# DISPC_VP1 register map
Vendor: Texas Instruments
Peripheral module from a debugger description file (folder TDA3x).
Registers are 32-bit, access per field, reset 0x0 unless marked. A register's access mark holds for its fields unless they carry their own. Offsets are as the file gives them; lines under a group give offsets from that group; [hi:lo] are bit positions; {n}, {i} and the like mark numbered series; 'fields as' and 'values as' point back to an identical list; <NAME> marks a mode.

## DISPC_VP1
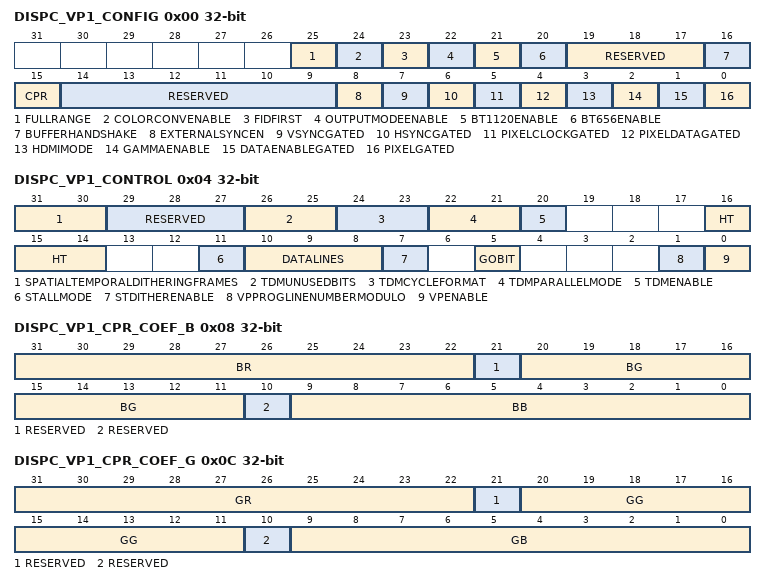
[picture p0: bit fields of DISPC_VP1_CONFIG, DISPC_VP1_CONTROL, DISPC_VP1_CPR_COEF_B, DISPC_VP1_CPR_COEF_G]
0x00 DISPC_VP1_CONFIG — The control register configures the Display Controller module for the VP output. Shadow register. Note: DSI, RFBI and HDMI are not supported in this family of devices.
  [25] FULLRANGE rw — Color Space Conversion full range setting.
    0=LIMRANGE (Limited range selected.); 1=FULLRANGE (Full range selected.)
  [24] COLORCONVENABLE rw — Enable the color space conversion. It shall be reset when CPR bit-field is set to 0x1.
    0=COLSPCDIS (Disable Color Space Conversion RGB to YUV); 1=COLSPCENB (Enable Color Space Conversion RGB to YUV)
  [23] FIDFIRST rw — Selects the first field to output in case of interlace mode. In case of progressive mode, the value is not used.
    0=EVEN (First field is even.); 1=ODD (Odd field is first.)
  [22] OUTPUTMODEENABLE rw — Selects between progressive and interlace mode for the VP output.
    0=DISABLE (Progressive mode selected.); 1=ENABLE (Interlace mode selected.)
  [21] BT1120ENABLE rw — Selects BT-1120 format on the VP output. It is not posssible to enable BT656 and BT1120 at the same time on the same VP output.
    0=DISABLE (BT-1120 is disabled.); 1=ENABLE (BT-1120 is enabled.)
  [20] BT656ENABLE rw — Selects BT-656 format on the VP output. It is not posssible to enable BT656 and BT1120 at the same time on the same VP output.
    0=DISABLE (BT-656 is disabled.); 1=ENABLE (BT-656 is enabled.)
  [19:17] RESERVED ro — Write 0's for future compatibility. Reads return 0
  [16] BUFFERHANDSHAKE rw — Controls the handsSHAKE between DMA buffer and STALL signal in order to prevent from underflow. The bit shall be set to 0 when the module is not in STALL mode.
    0=HANDCHECKDIS (Only the STALL signal (generated by RFBI or DSI2 depending on which IP uses the LCD output) is used regardless of the DMA buffer fullness information in order to provide data to the RFBI or DSI2 module.); 1=HANDCHECKENB (The STALL signal (generated by RFBI or DSI2 depending on which IP uses the LCD output) is used in combination with the DMA buffer fullness information in order to provide data to the RFBI or DSI2 module only when it does not generated buffer underflow.)
  [15] CPR rw — Color Phase Rotation Control VP output). It shall be reset when ColorConvEnable bit-field is set to 1. Shadow bit-field.
    0=CPRDIS (Color Phase Rotation Disabled); 1=CPRENB (Color Phase Rotation Enabled)
  [14:9] RESERVED ro — Write 0's for future compatibility. Reads return 0
  [8] EXTERNALSYNCEN rw — Selects between external sync and internal sync mode for the VP output.
    0=DISABLE (Internal sync mode selected); 1=ENABLE (External sync mode selected.)
  [7] VSYNCGATED rw — VSYNC Gated Enabled (VP output) Shadow bit-field.
    0=VGDIS (VSYNC Gated Disabled); 1=VGENB (VSYNC Gated Enabled)
  [6] HSYNCGATED rw — HSYNC Gated Enabled (VP output) Shadow bit-field.
    0=HGDIS (HSYNC Gated Disabled); 1=HGENB (HSYNC Gated Enabled)
  [5] PIXELCLOCKGATED rw — Pixel Clock Gated Enabled (VP output) Shadow bit-field.
    0=PCGDIS (Pixel Clock Gated Disabled); 1=PCGENB (Pixel Clock Gated Enabled)
  [4] PIXELDATAGATED rw — Pixel Data Gated Enabled (VP output) Shadow bit-field.
    0=PDGDIS (Pixel Data Gated Disabled); 1=PDGENB (Pixel Data Gated Enabled)
  [3] HDMIMODE rw — Configures the timing generator in HDMI compatible mode to generate same timings as HDMI wrapper timings.
    0=HDMIMODEDIS (Disable HDMI mode.); 1=HDMIMODEEN (Enable HDMI mode timings: - vertical FSM starts with the VFP period (instead of VSYNC) - last frame ends with the last pixel of data state.)
  [2] GAMMAENABLE rw — Enable the gamma Shadow bit-field.
    0=GAMMADIS (Gamma disabled); 1=GAMMAENB (Gamma enabled)
  [1] DATAENABLEGATED rw — DE Gated Enable Shadow bit-field.
    0=DEGDIS (DE signal is not gated); 1=DEGENB (DE signal is gated.)
  [0] PIXELGATED rw — Pixel Gated Enable Shadow bit-field.
    0=PCLKTOGA (Pixel clock always toggles (only in TFT mode)); 1=PCLKTOGV (Pixel clock only toggles when there is valid data to display. (only in TFT mode))
0x04 DISPC_VP1_CONTROL — The control register configures the Display Controller module for the VP output.
  [31:30] SPATIALTEMPORALDITHERINGFRAMES rw — Spatial/Temporal dithering number of frames for the VP output. Shadow bit-field.
    0=ONEFRAME (Spatial only); 1=TWOFRAMES (Spatial and temporal over 2 frames); 2=FOURFRAMES (Spatial and temporal over 4 frames)
  [29:27] RESERVED ro — Write 0's for future compatibility. Reads return 0
  [26:25] TDMUNUSEDBITS rw — State of unused bits (TDM mode only) for the VP output. Shadow bit-field.
    0=LOWLEVEL (low level (0)); 1=HIGHLEVEL (high level (1)); 2=UNCHANGED (unchanged from previous state)
  [24:23] TDMCYCLEFORMAT rw — Cycle format (TDM mode only) for the VP output. Shadow bit-field.
    0=_1CYCPERPIX (1 cycle for 1 pixel); 1=_2CYCPERPIX (2 cycles for 1 pixel); 3=_3CYCPER2PIX (3 cycles for 2 pixels); 2=_3CYCPERPIX (3 cycles for 1 pixel)
  [22:21] TDMPARALLELMODE rw — Output Interface width (TDM mode only) for the VP output. Shadow bit-field.
    0=_8BPARAINT (8-bit parallel output interface selected); 1=_9BPARAINT (9-bit parallel output interface selected); 3=_16BPARAINT (16-bit parallel output interface selected); 2=_12BPARAINT (12-bit parallel output interface selected)
  [20] TDMENABLE rw — Enable the multiple cycle format for the VP output. Shadow bit-field.
    0=TDMDIS (TDM disabled); 1=TDMENB (TDM enabled)
  [16:14] HT rw — Hold Time for VP output. Shadow bit-field. Encoded value (from 1 to 8) to specify the number of external digital clock periods to hold the data (programmed value = value minus one)
  [11] STALLMODE rw — STALL Mode for the VP output. Shadow bit-field.
    0=NMODE (Normal mode selected); 1=RFBIMODE (STALL mode selected. The Display Controller sends the data without considering the VSYNC/HSYNC. The VP output is disabled at the end of the transfer of the frame. The S/W has to re-enable the VP output in order to generate a new frame.)
  [10:8] DATALINES rw — Width of the data bus on VP output. Shadow bit-field.
    1=OALSB16B (16-bit output aligned on the LSB of the pixel data interface); 0=OALSB12B (12-bit output aligned on the LSB of the pixel data interface); 2=OALSB18B (18-bit output aligned on the LSB of the pixel data interface); 4=OALSB30B (30-bit output aligned on the LSB of the pixel data interface); 5=OALSB36B (36-bit output aligned on the LSB of the pixel data interface); 3=OALSB24B (24-bit output aligned on the LSB of the pixel data interface)
  [7] STDITHERENABLE rw — Spatial Temporal dithering enable for the VP output Shadow bit-field.
    0=STDITHDIS (Spatial/Temporal dithering logic disabled); 1=STDITHENB (Spatial/Temporal dithering logic enabled)
  [5] GOBIT rw — GO Command for the VP output. It is used to synchronized the pipelines associated with the VP output. wr:immediate
    0=HFUISR (The hardware has finished updating the internal shadow registers of the pipeline(s) connected to the VP output using the user values. The hardware resets the bit when the update is completed.); 1=UFPSR (The user has finished to program the shadow registers of the pipeline(s) associated with the VP output and the hardware can update the internal registers at the VFP start period)
  [1] VPPROGLINENUMBERMODULO rw — Enable the modulo of the line number interrupt generation
    0=MODDIS (Disable modulo); 1=MODEN (Enable Modulo)
  [0] VPENABLE rw — Enable the video port output wr:immediate
    0=LCDOPDIS (VP output disabled (at the end of the frame when the bit is reset)); 1=LCDOPENB (VP output enabled)
0x08 DISPC_VP1_CPR_COEF_B — The register configures the color phase rotation matrix coefficients for the Blue component. Shadow register.
  [31:22] BR rw — BR Coefficient Encoded signed value (from -512 to 511).
  [21] RESERVED ro — Write 0's for future compatibility. Reads return 0
  [20:11] BG rw — BG Coefficient Encoded signed value (from -512 to 511).
  [10] RESERVED ro — Write 0's for future compatibility. Reads return 0
  [9:0] BB rw — BB Coefficient Encoded signed value (from -512 to 511).
0x0C DISPC_VP1_CPR_COEF_G — The register configures the color phase rotation matrix coefficients for the Green component. Shadow register.
  [31:22] GR rw — GR Coefficient Encoded signed value (from -512 to 511).
  [21] RESERVED ro — Write 0's for future compatibility. Reads return 0
  [20:11] GG rw — GG Coefficient Encoded signed value (from -512 to 511).
  [10] RESERVED ro — Write 0's for future compatibility. Reads return 0
  [9:0] GB rw — GB Coefficient Encoded signed value (from -512 to 511).
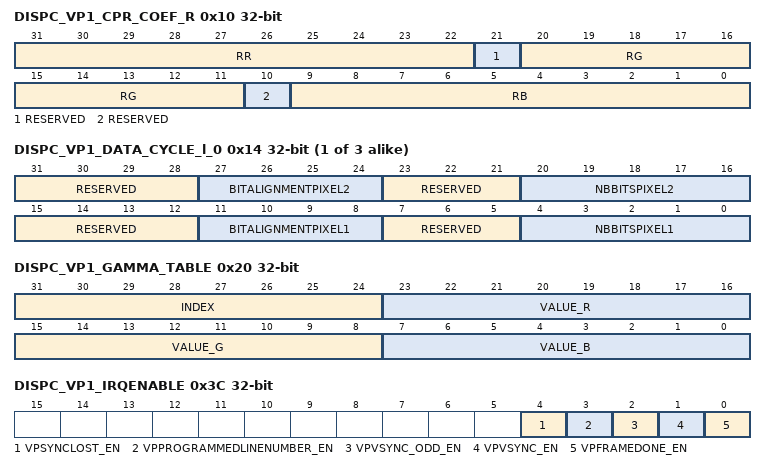
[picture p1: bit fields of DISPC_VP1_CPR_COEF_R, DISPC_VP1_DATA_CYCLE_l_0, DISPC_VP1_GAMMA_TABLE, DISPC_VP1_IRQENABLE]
0x10 DISPC_VP1_CPR_COEF_R — The register configures the color phase rotation matrix coefficients for the Red component. Shadow register.
  [31:22] RR rw — RR Coefficient Encoded signed value (from -512 to 511).
  [21] RESERVED ro — Write 0's for future compatibility. Reads return 0
  [20:11] RG rw — RG Coefficient Encoded signed value (from -512 to 511).
  [10] RESERVED ro — Write 0's for future compatibility. Reads return 0
  [9:0] RB rw — RB Coefficient Encoded signed value (from -512 to 511).
{0x14+4i} DISPC_VP1_DATA_CYCLE_l_{i} (i=0..2) — The control register configures the output data format over up to 3 cycles. Shadow register.
  [31:28] RESERVED ro — Write 0's for future compatibility. Reads return 0
  [27:24] BITALIGNMENTPIXEL2 rw — Bit alignment Alignment of the bits from pixel#2 on the output interface
  [23:21] RESERVED ro — Write 0's for future compatibility. Reads return 0
  [20:16] NBBITSPIXEL2 rw — Number of bits Number of bits from the pixel #2 (value from 0 to 16 bits). The values from 17 to 31 are invalid.
  [15:12] RESERVED ro — Write 0's for future compatibility. Reads return 0
  [11:8] BITALIGNMENTPIXEL1 rw — Bit alignment Alignment of the bits from pixel#1 on the output interface
  [7:5] RESERVED ro — Write 0's for future compatibility. Reads return 0
  [4:0] NBBITSPIXEL1 rw — Number of bits Number of bits from the pixel #1 (value from 0 to 16 bits). The values from 17 to 31 are invalid.
0x20 DISPC_VP1_GAMMA_TABLE wo — The register configures the gamma table on VP output.
  [31:24] INDEX — Defines the location in the table where the bit-field VALUE is stored
  [23:16] VALUE_R — 8-bit value used to defined the value to be stored in the gamma table
  [15:8] VALUE_G — 8-bit value used to defined the value to be stored in the gamma table
  [7:0] VALUE_B — 8-bit value used to defined the value to be stored in the gamma table
0x3C DISPC_VP1_IRQENABLE — This register allows to mask/unmask the module internal sources of interrupt, on an event-by-event basis
  [4] VPSYNCLOST_EN rw — Synchronization Lost for Video Port.
    0=MASKED (SyncLost for the primary VP output is masked); 1=GENINT (SyncLost for the primary VP output generates an interrupt when it occurs)
  [3] VPPROGRAMMEDLINENUMBER_EN rw — Programmed Line Number. It indicates that the scan of the display has reached the programmed user line number.
    0=MASKED (ProgrammedLineNumber is masked); 1=GENINT (ProgrammedLineNumber generates an interrupt when it occurs)
  [2] VPVSYNC_ODD_EN rw — VSYNC for odd field from interlace mode only.
    0=MASKED (EVSYNC_ODD for the VP output is masked); 1=GENINT (EVSYNC_ODD for the VP output generates an interrupt when it occurs)
  [1] VPVSYNC_EN rw — Vertical Synchronization for VP.
    0=MASKED (VSYNC for the primary VP output is masked); 1=GENINT (VSYNC for the primary VP output generates an interrupt when it occurs)
  [0] VPFRAMEDONE_EN rw — Frame Done for Video Port. VP output has been disabled by user. All the data have been sent.
    0=MASKED (FrameDone for the primary VP output is masked); 1=GENINT (FrameDone for the primary VP output generates an interrupt when it occurs)
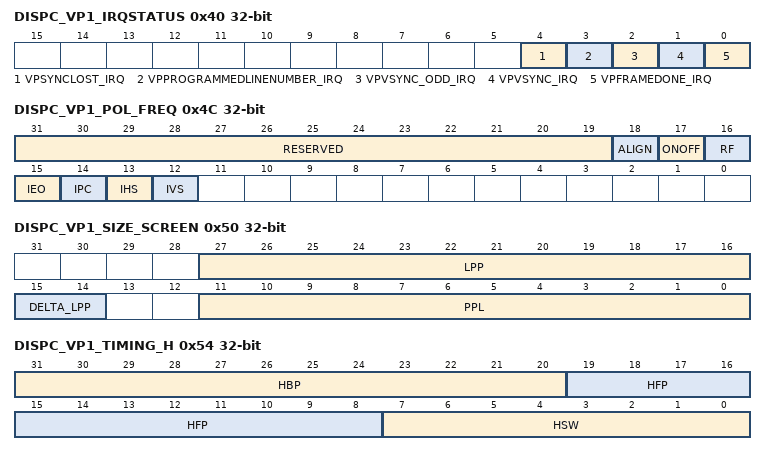
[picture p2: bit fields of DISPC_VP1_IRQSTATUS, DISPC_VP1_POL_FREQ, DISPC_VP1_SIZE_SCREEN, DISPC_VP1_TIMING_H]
0x40 DISPC_VP1_IRQSTATUS — This register regroups all the status of the module internal events that generate an interrupt. Write 1 to a given bit resets this bit
  [all] fields
    0=FALSE (READS: Event is false. WRITES: Status bit unchanged.); 1=TRUE (READS: Event is true (pending). WRITES: Status bit is reset.)
  [4] VPSYNCLOST_IRQ rw — Synchronization Lost on VP output. The required data are not output at the correct time due to too short blanking periods or stall of at least one pipelines associated with VP output.
  [3] VPPROGRAMMEDLINENUMBER_IRQ rw — Programmed Line Number. It indicates that the scan of the display has reached the programmed user line number.
  [2] VPVSYNC_ODD_IRQ rw — VSYNC for odd field from interlace mode only.
  [1] VPVSYNC_IRQ rw — Vertical Synchronization for VP output. It is used as VSYNC_EVEN in case of interlace mode.
  [0] VPFRAMEDONE_IRQ rw — Frame Done for VP. VP output has been disabled by user. All the data have been sent.
0x44 DISPC_VP1_LINE_NUMBER — The control register indicates the panel display line number for the interrupt and the DMA request. Shadow register.
  [11:0] LINENUMBER rw — Display panel line number programming. Line number defines the line on which the programmable interrupt is generated and the DMA request occurs.
0x48 DISPC_VP1_LINE_STATUS ro — The control register indicates the panel display line number.
  [11:0] LINENUMBER — Current display panel line number. Current display line number. The first active line has the value '0'. During blanking lines the line number is not incremented.
0x4C DISPC_VP1_POL_FREQ — The register configures the signal configuration. Shadow register.
  [31:19] RESERVED ro — Write 0's for future compatibility. Reads return 0
  [18] ALIGN rw — Defines the alignment betwwen HSYNC and VSYNC assertion.
    0=NOTALIGNED (VSYNC and HSYNC are not aligned); 1=ALIGNED (VSYNC and HSYNC assertions are aligned.)
  [17] ONOFF rw — HSYNC/VSYNC Pixel clock Control On/Off
    0=DOPEDPCK (HSYNC and VSYNC are driven on opposite edges of pixel clock than pixel data); 1=DBIT16 (HSYNC and VSYNC are driven according to bit 16)
  [16] RF rw — Program HSYNC/VSYNC Rise or Fall
    0=DFEDPCK (HSYNC and VSYNC are driven on falling edge of pixel clock (if bit 17 set to 1)); 1=DRIEDPCK (HSYNC and VSYNC are driven on rising edge of pixel clock (if bit 17 set to 1))
  [15] IEO rw — Invert output enable
    0=ACBAHIGH (Ac-bias is active high (active display mode)); 1=ACBALOW (Ac-bias is active low (active display mode))
  [14] IPC rw — Invert pixel clock
    0=DRPCK (Data is driven on the VP data lines on the rising-edge of the pixel clock); 1=DFPCK (Data is driven on the VP data lines on the falling-edge of the pixel clock)
  [13] IHS rw — Invert HSYNC
    0=LCKPINAH (Line clock pin is active high and inactive low); 1=LCKPINAL (Line clock pin is active low and inactive high)
  [12] IVS rw — Invert VSYNC
    0=FCKPINAH (Frame clock pin is active high and inactive low); 1=FCKPINAL (Frame clock pin is active low and inactive high)
0x50 DISPC_VP1_SIZE_SCREEN — The register configures the panel size (horizontal and vertical). Shadow register. A delta value is used to indicate if the odd field has same vertical size as the even field or +/- one line.
  [27:16] LPP rw — Lines per panel Encoded value (from 1 to 4096) to specify the number of lines per panel (program to value minus one).
  [15:14] DELTA_LPP rw — Indicates the delta size value of the odd field compared to the even field
    0=SAME (same size); 1=PLUSONE (odd size = even size +1); 2=MINUSONE (Odd size = even size -1)
  [11:0] PPL rw — Pixels per line Encoded value (from 1 to 4096) to specify the number of pixels contains within each line on the display (program to value minus one). In STALL mode, any value is valid. In non STALL mode, only values multiple of 8 pixels are valiid.
0x54 DISPC_VP1_TIMING_H rw — The register configures the timing logic for the HSYNC signal. Shadow register.
  [31:20] HBP — Horizontal Back Porch. Encoded value (from 1 to 4096) to specify the number of pixel clock periods to add to the beginning of a line transmission before the first set of pixels is output to the displaydisplay (program to value minus one). When in BT mode and interlaced, this field corresponds to the vertical field blanking No 2 for Even Field.
  [19:8] HFP — Horizontal front porch. Encoded value (from 1 to 4096) to specify the number of pixel clock periods to add to the end of a line transmission before line clock is asserted display (program to value minus one). When in BT mode and interlaced, this field corresponds to the vertical field blanking No 1 for Even Field.
  [7:0] HSW — Horizontal synchronization pulse width Encoded value (from 1 to 256) to specify the number of pixel clock periods to pulse the line clock at the end of each line display (program to value minus one). When in BT mode, this field corresponds to the LSB 8-bits of the 12-bit horizontal blanking(BT_HBLANK[11:0]= {VSW[3:0],HSW[7:0]}).
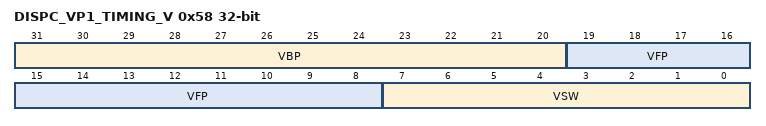
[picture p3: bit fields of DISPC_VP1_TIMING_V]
0x58 DISPC_VP1_TIMING_V rw — The register configures the timing logic for the VSYNC signal. Shadow register.
  [31:20] VBP — Vertical back porch Encoded value (from 0 to 4095) to specify the number of line clock periods to add to the beginning of a frame. When in BT mode and interlaced, this field corresponds to the vertical field blanking No 2 for Odd Field. When in BT and in progressive mode, this field corresponds to the Vertical frame blanking No 2 . before the first set of pixels is output to the display.
  [19:8] VFP — Vertical front porch Encoded value (from 0 to 4095) to specify the number of line clock periods to add to the end of each frame. When in BT mode and interlaced, this field corresponds to the vertical field blanking No 1 for Odd Field. When in BT and in progressive mode, this field corresponds to the Vertical frame blanking No 2 .
  [7:0] VSW — Vertical synchronization pulse width Encoded value (from 1 to 256) to specify the number of line clock periods (program to value minus one) to pulse the frame clock (VSYNC) pin at the end of each frame after the end of frame wait (VFP) period elapses. Frame clock uses as VSYNC signal in active mode. When in BT mode, the lsb 4-bits of this field (VSW[3:0]) corresponds to the MSB 4-bits of the 12-bit horizontal blanking(BT_HBLANK= {VSW[3:0],HSW[7:0]}).
